AUTOSAR XML (schema 00049)
standard types defined: boolean, uint8, boolean_CompuMethod, boolean_DataConstr
package /ComponentTypes
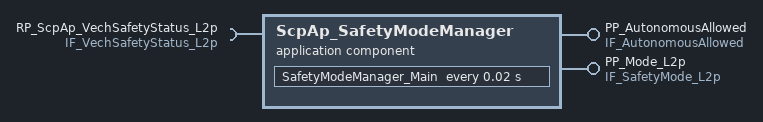
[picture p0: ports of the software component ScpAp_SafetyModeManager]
  application sw component type ScpAp_SafetyModeManager
    provide port PP_AutonomousAllowed: nonqueued-sender-com-spec{data-element=IF_AutonomousAllowed, init-value=0}, provided-interface=IF_AutonomousAllowed
    provide port PP_Mode_L2p: nonqueued-sender-com-spec{data-element=IF_SafetyMode_L2p, init-value=1}, provided-interface=IF_SafetyMode_L2p
    require port RP_ScpAp_VechSafetyStatus_L2p: nonqueued-receiver-com-spec{data-element=IF_VechSafetyStatus_L2p, filter=data-filter-type=ALWAYS, init-value=0}, required-interface=IF_VechSafetyStatus_L2p
    behavior ScpAp_SafetyModeManager_InternalBehavior: handle-termination-and-restart=NO-SUPPORT
      timing event TMT_SafetyModeManager_Main: start-on-event=SafetyModeManager_Main, period=0.02
      runnable SafetyModeManager_Main
        data-receive-point-by-arguments:
          access REC_RP_ScpAp_VechSafetyStatus_L2p_IF_VechSafetyStatus_L2p: accessed-variable=RP_ScpAp_VechSafetyStatus_L2p.IF_VechSafetyStatus_L2p
        data-send-points:
          access SEND_PP_AutonomousAllowed_IF_AutonomousAllowed: accessed-variable=PP_AutonomousAllowed.IF_AutonomousAllowed
          access SEND_PP_Mode_L2p_IF_SafetyMode_L2p: accessed-variable=PP_Mode_L2p.IF_SafetyMode_L2p
  swc implementation ScpAp_SafetyModeManager_Implementation: behavior=ScpAp_SafetyModeManager_InternalBehavior
    code-descriptors:
      code Default: artifact-descriptors=autosar-engineering-object={short-label=Default, category=SWSRC}
package /DataTypes
  impl type SafetyMode_L2p_IDT: category=VALUE, base-type=BaseTypes/uint8, sw-calibration-access=READ-ONLY, compu {0=MANUAL (CompuScale), 1=AUTONOMOUS (CompuScale), 3=TELEOPS (CompuScale)}, type-emitter=RTE
  impl type VechSafetyStatus_L2p_IDT: category=VALUE, base-type=BaseTypes/uint8, sw-calibration-access=READ-ONLY, compu {0=NORMAL (CompuScale), 1=DEGRADED (CompuScale), 3=FAULT_STOP (CompuScale)}, type-emitter=RTE
package /PortInterfaces
  sender receiver interface IF_AutonomousAllowed: invalidation-policy{data-element=IF_AutonomousAllowed, handle-invalid=DONT-INVALIDATE}
    data IF_AutonomousAllowed: type=boolean
  sender receiver interface IF_SafetyMode_L2p: invalidation-policy{data-element=IF_SafetyMode_L2p, handle-invalid=DONT-INVALIDATE}
    data IF_SafetyMode_L2p: type=SafetyMode_L2p_IDT
  sender receiver interface IF_VechSafetyStatus_L2p: invalidation-policy{data-element=IF_VechSafetyStatus_L2p, handle-invalid=DONT-INVALIDATE}
    data IF_VechSafetyStatus_L2p: type=VechSafetyStatus_L2p_IDT
